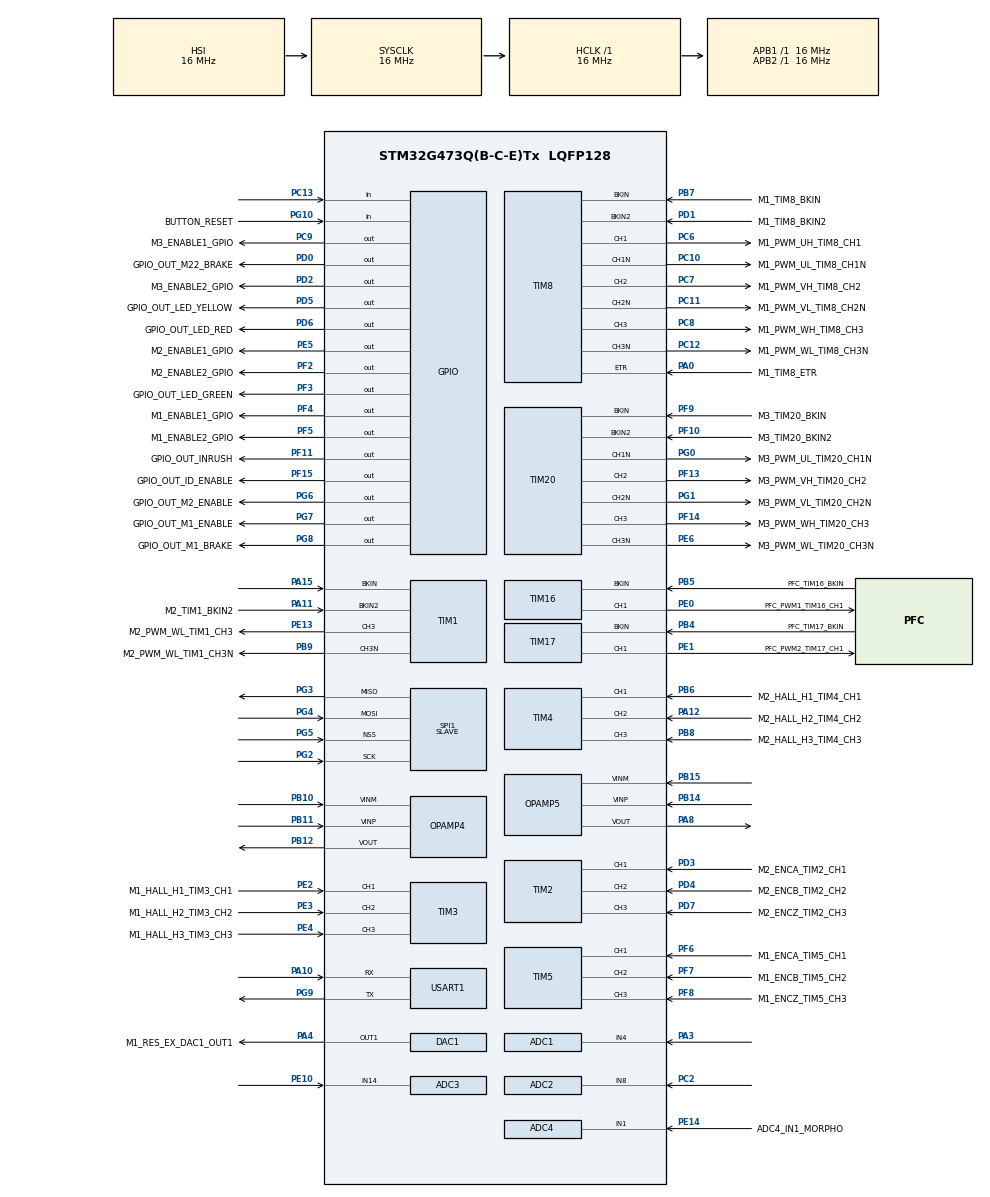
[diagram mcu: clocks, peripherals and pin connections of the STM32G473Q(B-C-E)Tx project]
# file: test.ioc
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ADC1.Channel-0\#ChannelRegularConversion=ADC_CHANNEL_4
ADC1.ClockPrescaler=ADC_CLOCK_SYNC_PCLK_DIV1
ADC1.ContinuousConvMode=ENABLE
ADC1.DMAAccessModeView=ENABLE
ADC1.DMAContinuousRequests=ENABLE
ADC1.Mode=ADC_DUALMODE_REGSIMULT
ADC1.NbrOfConversionFlag=1
ADC1.OffsetNumber-0\#ChannelRegularConversion=ADC_OFFSET_NONE
ADC1.Rank-0\#ChannelRegularConversion=1
ADC1.SamplingTime-0\#ChannelRegularConversion=ADC_SAMPLETIME_2CYCLES_5
ADC1.TwoSamplingDelay=ADC_TWOSAMPLINGDELAY_12CYCLES
ADC1.master=1
ADC2.Channel-1\#ChannelRegularConversion=ADC_CHANNEL_8
ADC2.ClockPrescaler=ADC_CLOCK_SYNC_PCLK_DIV1
ADC2.ContinuousConvMode=ENABLE
ADC2.DMAAccessModeView=ENABLE
ADC2.DMAContinuousRequests=DISABLE
ADC2.EnableAnalogWatchDog3=false
ADC2.Mode=ADC_DUALMODE_REGSIMULT
ADC2.NbrOfConversion=1
ADC2.NbrOfConversionFlag=1
ADC2.OffsetNumber-1\#ChannelRegularConversion=ADC_OFFSET_NONE
ADC2.Overrun=ADC_OVR_DATA_PRESERVED
ADC2.Rank-1\#ChannelRegularConversion=1
ADC2.Resolution=ADC_RESOLUTION_12B
ADC2.SamplingTime-1\#ChannelRegularConversion=ADC_SAMPLETIME_2CYCLES_5
ADC2.TwoSamplingDelay=ADC_TWOSAMPLINGDELAY_12CYCLES
ADC3.Channel-2\#ChannelRegularConversion=ADC_CHANNEL_14
ADC3.ClockPrescaler=ADC_CLOCK_SYNC_PCLK_DIV1
ADC3.ContinuousConvMode=ENABLE
ADC3.DMAAccessModeView=ENABLE
ADC3.DMAContinuousRequests=ENABLE
ADC3.Mode=ADC_DUALMODE_REGSIMULT
ADC3.NbrOfConversionFlag=1
ADC3.OffsetNumber-2\#ChannelRegularConversion=ADC_OFFSET_NONE
ADC3.Rank-2\#ChannelRegularConversion=1
ADC3.SamplingTime-2\#ChannelRegularConversion=ADC_SAMPLETIME_2CYCLES_5
ADC3.TwoSamplingDelay=ADC_TWOSAMPLINGDELAY_12CYCLES
ADC3.master=1
ADC4.Channel-1\#ChannelRegularConversion=ADC_CHANNEL_1
ADC4.ClockPrescaler=ADC_CLOCK_SYNC_PCLK_DIV1
ADC4.DMAAccessModeView=ENABLE
ADC4.Mode=ADC_DUALMODE_REGSIMULT
ADC4.NbrOfConversionFlag=1
ADC4.OffsetNumber-1\#ChannelRegularConversion=ADC_OFFSET_NONE
ADC4.Rank-1\#ChannelRegularConversion=1
ADC4.SamplingTime-1\#ChannelRegularConversion=ADC_SAMPLETIME_2CYCLES_5
ADC4.TwoSamplingDelay=ADC_TWOSAMPLINGDELAY_12CYCLES
DAC1.DAC_Channel-DAC_OUT2_ExtAndInt=DAC_CHANNEL_2
Dma.ADC1.0.Direction=DMA_PERIPH_TO_MEMORY
Dma.ADC1.0.EventEnable=DISABLE
Dma.ADC1.0.Instance=DMA1_Channel4
Dma.ADC1.0.MemDataAlignment=DMA_MDATAALIGN_WORD
Dma.ADC1.0.MemInc=DMA_MINC_ENABLE
Dma.ADC1.0.Mode=DMA_CIRCULAR
Dma.ADC1.0.PeriphDataAlignment=DMA_PDATAALIGN_WORD
Dma.ADC1.0.PeriphInc=DMA_PINC_DISABLE
Dma.ADC1.0.Polarity=HAL_DMAMUX_REQ_GEN_RISING
Dma.ADC1.0.Priority=DMA_PRIORITY_HIGH
Dma.ADC1.0.RequestNumber=1
Dma.ADC1.0.SignalID=NONE
Dma.ADC1.0.SyncEnable=DISABLE
Dma.ADC1.0.SyncPolarity=HAL_DMAMUX_SYNC_NO_EVENT
Dma.ADC1.0.SyncRequestNumber=1
Dma.ADC1.0.SyncSignalID=NONE
Dma.ADC3.1.Direction=DMA_PERIPH_TO_MEMORY
Dma.ADC3.1.EventEnable=DISABLE
Dma.ADC3.1.Instance=DMA2_Channel1
Dma.ADC3.1.MemDataAlignment=DMA_MDATAALIGN_WORD
Dma.ADC3.1.MemInc=DMA_MINC_ENABLE
Dma.ADC3.1.Mode=DMA_CIRCULAR
Dma.ADC3.1.PeriphDataAlignment=DMA_PDATAALIGN_WORD
Dma.ADC3.1.PeriphInc=DMA_PINC_DISABLE
Dma.ADC3.1.Polarity=HAL_DMAMUX_REQ_GEN_RISING
Dma.ADC3.1.Priority=DMA_PRIORITY_HIGH
Dma.ADC3.1.RequestNumber=1
Dma.ADC3.1.SignalID=NONE
Dma.ADC3.1.SyncEnable=DISABLE
Dma.ADC3.1.SyncPolarity=HAL_DMAMUX_SYNC_NO_EVENT
Dma.ADC3.1.SyncRequestNumber=1
Dma.ADC3.1.SyncSignalID=NONE
Dma.Request0=ADC1
Dma.Request1=ADC3
Mcu.Family=STM32G4
Mcu.Name=STM32G473Q(B-C-E)Tx
Mcu.Package=LQFP128
NVIC.ADC1_2_IRQn=true\:1\:0\:true\:false\:true\:true\:true\:true
NVIC.DMA1_Channel4_IRQn=true\:0\:0\:false\:false\:true\:false\:true\:true
NVIC.DMA2_Channel1_IRQn=true\:0\:0\:false\:false\:true\:false\:true\:true
NVIC.PriorityGroup=NVIC_PRIORITYGROUP_4
PA0.GPIO_Label=M1_TIM8_ETR
PA0.Signal=S_TIM8_ETR
PA10.Mode=Asynchronous
PA10.Signal=USART1_RX
PA11.GPIO_Label=M2_TIM1_BKIN2
PA11.Mode=Activate-Break-Input-2
PA11.Signal=TIM1_BKIN2
PA12.GPIO_Label=M2_HALL_H2_TIM4_CH2
PA12.Signal=S_TIM4_CH2
PA13.Mode=Trace_Asynchronous_SW
PA13.Signal=SYS_JTMS-SWDIO
PA14.Mode=Trace_Asynchronous_SW
PA14.Signal=SYS_JTCK-SWCLK
PA15.Mode=Activate-Break-Input
PA15.Signal=TIM1_BKIN
PA2.GPIO_Mode=GPIO_MODE_ANALOG
PA2.GPIO_PuPd=GPIO_NOPULL
PA2.Signal=ADC1_IN3
PA3.Mode=IN4-Single-Ended
PA3.Signal=ADC1_IN4
PA4.GPIO_Label=M1_RES_EX_DAC1_OUT1
PA4.Signal=COMP_DAC11_group
PA6.GPIO_Label=M3_TEMP_ID_ADC2IN3
PA6.Signal=ADC2_IN3
PA8.Mode=Standalone
PA8.Signal=OPAMP5_VOUT
PB0.Signal=OPAMP3_VINP
PB1.Signal=OPAMP3_VOUT
PB10.Mode=Standalone
PB10.Signal=OPAMP4_VINM
PB11.Mode=Standalone
PB11.Signal=OPAMP4_VINP
PB12.Mode=Standalone
PB12.Signal=OPAMP4_VOUT
PB13.GPIO_Label=M1_VBUS_ADC3_IN5
PB13.Signal=ADC3_IN5
PB14.Mode=Standalone
PB14.Signal=OPAMP5_VINP
PB15.Mode=Standalone
PB15.Signal=OPAMP5_VINM
PB3.Mode=Trace_Asynchronous_SW
PB3.Signal=SYS_JTDO-SWO
PB4.GPIO_Label=PFC_TIM17_BKIN
PB4.Mode=Activate-Break-Input
PB4.Signal=TIM17_BKIN
PB5.GPIO_Label=PFC_TIM16_BKIN
PB5.Mode=Activate-Break-Input
PB5.Signal=TIM16_BKIN
PB6.GPIO_Label=M2_HALL_H1_TIM4_CH1
PB6.Signal=S_TIM4_CH1
PB7.GPIO_Label=M1_TIM8_BKIN
PB7.Mode=Activate-Break-Input
PB7.Signal=TIM8_BKIN
PB8-BOOT0.GPIO_Label=M2_HALL_H3_TIM4_CH3
PB8-BOOT0.Signal=S_TIM4_CH3
PB9.GPIO_Label=M2_PWM_WL_TIM1_CH3N
PB9.Mode=PWM Generation3 CH3 CH3N
PB9.Signal=TIM1_CH3N
PC0.Signal=ADC2_IN6
PC10.GPIO_Label=M1_PWM_UL_TIM8_CH1N
PC10.Mode=PWM Generation1 CH1 CH1N
PC10.Signal=TIM8_CH1N
PC11.GPIO_Label=M1_PWM_VL_TIM8_CH2N
PC11.Mode=Output Compare2 CH2 CH2N
PC11.Signal=TIM8_CH2N
PC12.GPIO_Label=M1_PWM_WL_TIM8_CH3N
PC12.Mode=Output Compare3 CH3 CH3N
PC12.Signal=TIM8_CH3N
PC13.GPIO_PuPd=GPIO_PULLUP
PC13.Signal=GPIO_Input
PC14-OSC32_IN.Mode=LSE-External-Oscillator
PC14-OSC32_IN.Signal=RCC_OSC32_IN
PC15-OSC32_OUT.Mode=LSE-External-Oscillator
PC15-OSC32_OUT.Signal=RCC_OSC32_OUT
PC2.GPIO_Mode=GPIO_MODE_ANALOG
PC2.GPIO_PuPd=GPIO_NOPULL
PC2.Mode=IN8-Single-Ended
PC2.Signal=ADC2_IN8
PC3.Signal=ADC2_IN9
PC4.GPIO_Label=M2_TEMP_ID_ADC2_IN5
PC4.Signal=ADC2_IN5
PC5.GPIO_Label=PFC_AC_ZC_ADC2_IN11
PC5.Signal=ADC2_IN11
PC6.GPIO_Label=M1_PWM_UH_TIM8_CH1
PC6.Signal=S_TIM8_CH1
PC7.GPIO_Label=M1_PWM_VH_TIM8_CH2
PC7.Signal=S_TIM8_CH2
PC8.GPIO_Label=M1_PWM_WH_TIM8_CH3
PC8.Signal=S_TIM8_CH3
PC9.GPIO_Label=M3_ENABLE1_GPIO
PC9.Signal=GPIO_Output
PD0.GPIO_Label=GPIO_OUT_M22_BRAKE
PD0.Signal=GPIO_Output
PD1.GPIO_Label=M1_TIM8_BKIN2
PD1.Mode=Activate-Break-Input-2
PD1.Signal=TIM8_BKIN2
PD2.GPIO_Label=M3_ENABLE2_GPIO
PD2.Signal=GPIO_Output
PD3.GPIO_Label=M2_ENCA_TIM2_CH1
PD3.Signal=S_TIM2_CH1
PD4.GPIO_Label=M2_ENCB_TIM2_CH2
PD4.Signal=S_TIM2_CH2
PD5.GPIO_Label=GPIO_OUT_LED_YELLOW
PD5.Signal=GPIO_Output
PD6.GPIO_Label=GPIO_OUT_LED_RED
PD6.Signal=GPIO_Output
PD7.GPIO_Label=M2_ENCZ_TIM2_CH3
PD7.Signal=S_TIM2_CH3
PE0.GPIO_Label=PFC_PWM1_TIM16_CH1
PE0.Signal=S_TIM16_CH1
PE1.GPIO_Label=PFC_PWM2_TIM17_CH1
PE1.Signal=S_TIM17_CH1
PE10.Mode=IN14-Single-Ended
PE10.Signal=ADC3_IN14
PE11.GPIO_Label=M2_PWM_VH_TIM1_CH2
PE11.Signal=S_TIM1_CH2
PE13.GPIO_Label=M2_PWM_WL_TIM1_CH3
PE13.Signal=S_TIM1_CH3
PE14.GPIO_Label=ADC4_IN1_MORPHO
PE14.Mode=IN1-Single-Ended
PE14.Signal=ADC4_IN1
PE15.GPIO_Label=M1_TEMP_ID_ADC4_IN2
PE15.Signal=ADC4_IN2
PE2.GPIO_Label=M1_HALL_H1_TIM3_CH1
PE2.Signal=S_TIM3_CH1
PE3.GPIO_Label=M1_HALL_H2_TIM3_CH2
PE3.Signal=S_TIM3_CH2
PE4.GPIO_Label=M1_HALL_H3_TIM3_CH3
PE4.Signal=S_TIM3_CH3
PE5.GPIO_Label=M2_ENABLE1_GPIO
PE5.Signal=GPIO_Output
PE6.GPIO_Label=M3_PWM_WL_TIM20_CH3N
PE6.Mode=Output Compare3 CH3 CH3N
PE6.Signal=TIM20_CH3N
PE9.GPIO_Label=M2_PWM_UH_TIM1_CH1
PE9.Signal=S_TIM1_CH1
PF0-OSC_IN.Mode=HSE-External-Clock-Source
PF0-OSC_IN.Signal=RCC_OSC_IN
PF1-OSC_OUT.GPIO_Label=ADC2_IN10_PFC_AC_V
PF1-OSC_OUT.Signal=ADC2_IN10
PF10.GPIO_Label=M3_TIM20_BKIN2
PF10.Mode=Activate-Break-Input-2
PF10.Signal=TIM20_BKIN2
PF11.GPIO_Label=GPIO_OUT_INRUSH
PF11.Signal=GPIO_Output
PF12.GPIO_Label=M3_PWM_UH_TIM20_CH1
PF12.Signal=S_TIM20_CH1
PF13.GPIO_Label=M3_PWM_VH_TIM20_CH2
PF13.Signal=S_TIM20_CH2
PF14.GPIO_Label=M3_PWM_WH_TIM20_CH3
PF14.Signal=S_TIM20_CH3
PF15.GPIO_Label=GPIO_OUT_ID_ENABLE
PF15.Signal=GPIO_Output
PF2.GPIO_Label=M2_ENABLE2_GPIO
PF2.GPIO_PuPd=GPIO_NOPULL
PF2.GPIO_Speed=GPIO_SPEED_FREQ_VERY_HIGH
PF2.Signal=GPIO_Output
PF3.GPIO_Label=GPIO_OUT_LED_GREEN
PF3.Signal=GPIO_Output
PF4.GPIO_Label=M1_ENABLE1_GPIO
PF4.Signal=GPIO_Output
PF5.GPIO_Label=M1_ENABLE2_GPIO
PF5.Signal=GPIO_Output
PF6.GPIO_Label=M1_ENCA_TIM5_CH1
PF6.Signal=S_TIM5_CH1
PF7.GPIO_Label=M1_ENCB_TIM5_CH2
PF7.Signal=S_TIM5_CH2
PF8.GPIO_Label=M1_ENCZ_TIM5_CH3
PF8.Signal=S_TIM5_CH3
PF9.GPIO_Label=M3_TIM20_BKIN
PF9.Mode=Activate-Break-Input
PF9.Signal=TIM20_BKIN
PG0.GPIO_Label=M3_PWM_UL_TIM20_CH1N
PG0.Mode=PWM Generation1 CH1 CH1N
PG0.Signal=TIM20_CH1N
PG1.GPIO_Label=M3_PWM_VL_TIM20_CH2N
PG1.Mode=PWM Generation2 CH2 CH2N
PG1.Signal=TIM20_CH2N
PG10-NRST.GPIO_Label=BUTTON_RESET
PG10-NRST.Signal=GPIO_Input
PG2.Mode=Full_Duplex_Slave
PG2.Signal=SPI1_SCK
PG3.Mode=Full_Duplex_Slave
PG3.Signal=SPI1_MISO
PG4.Mode=Full_Duplex_Slave
PG4.Signal=SPI1_MOSI
PG5.Mode=NSS_Signal_Hard_Input
PG5.Signal=SPI1_NSS
PG6.GPIO_Label=GPIO_OUT_M2_ENABLE
PG6.Signal=GPIO_Output
PG7.GPIO_Label=GPIO_OUT_M1_ENABLE
PG7.Signal=GPIO_Output
PG8.GPIO_Label=GPIO_OUT_M1_BRAKE
PG8.Signal=GPIO_Output
PG9.Mode=Asynchronous
PG9.Signal=USART1_TX
ProjectManager.HeapSize=0x200
ProjectManager.StackSize=0x400
ProjectManager.TargetToolchain=STM32CubeIDE
RCC.ADC12Freq_Value=16000000
RCC.ADC345Freq_Value=16000000
RCC.AHBFreq_Value=16000000
RCC.APB1Freq_Value=16000000
RCC.APB1TimFreq_Value=16000000
RCC.APB2Freq_Value=16000000
RCC.APB2TimFreq_Value=16000000
RCC.CortexFreq_Value=16000000
RCC.EXTERNAL_CLOCK_VALUE=12288000
RCC.HCLKFreq_Value=16000000
RCC.HSE_VALUE=8000000
RCC.HSI48_VALUE=48000000
RCC.HSI_VALUE=16000000
RCC.SYSCLKFreq_VALUE=16000000
RCC.USBFreq_Value=64000000
RCC.VCOOutputFreq_Value=128000000
SH.COMP_DAC11_group.0=DAC1_OUT1,DAC_OUT1_ExtAndInt
SH.S_TIM16_CH1.0=TIM16_CH1,Output Compare1 CH1
SH.S_TIM17_CH1.0=TIM17_CH1,Output Compare1 CH1
SH.S_TIM1_CH1.0=TIM1_CH1
SH.S_TIM1_CH2.0=TIM1_CH2
SH.S_TIM1_CH3.0=TIM1_CH3,PWM Generation3 CH3 CH3N
SH.S_TIM20_CH1.0=TIM20_CH1
SH.S_TIM20_CH2.0=TIM20_CH2,PWM Generation2 CH2 CH2N
SH.S_TIM20_CH3.0=TIM20_CH3,Output Compare3 CH3 CH3N
SH.S_TIM2_CH1.0=TIM2_CH1,Encoder_Interface
SH.S_TIM2_CH2.0=TIM2_CH2,Encoder_Interface
SH.S_TIM2_CH3.0=TIM2_CH3,Input_Capture3_from_TI3
SH.S_TIM3_CH1.0=TIM3_CH1,Xored_Inputs_Hall_Sensor_Interface
SH.S_TIM3_CH2.0=TIM3_CH2,Xored_Inputs_Hall_Sensor_Interface
SH.S_TIM3_CH3.0=TIM3_CH3,Xored_Inputs_Hall_Sensor_Interface
SH.S_TIM4_CH1.0=TIM4_CH1,Xored_Inputs_Hall_Sensor_Interface
SH.S_TIM4_CH2.0=TIM4_CH2,Xored_Inputs_Hall_Sensor_Interface
SH.S_TIM4_CH3.0=TIM4_CH3,Xored_Inputs_Hall_Sensor_Interface
SH.S_TIM5_CH1.0=TIM5_CH1,Encoder_Interface
SH.S_TIM5_CH2.0=TIM5_CH2,Encoder_Interface
SH.S_TIM5_CH3.0=TIM5_CH3,Input_Capture3_from_TI3
SH.S_TIM8_CH1.0=TIM8_CH1,PWM Generation1 CH1 CH1N
SH.S_TIM8_CH2.0=TIM8_CH2,Output Compare2 CH2 CH2N
SH.S_TIM8_CH3.0=TIM8_CH3,Output Compare3 CH3 CH3N
SH.S_TIM8_ETR.0=TIM8_ETR,ETR-as-clearing-source
SPI1.Direction=SPI_DIRECTION_2LINES
SPI1.Mode=SPI_MODE_SLAVE
SPI1.VirtualNSS=VM_NSSHARD
SPI1.VirtualType=VM_SLAVE
TIM1.Channel-PWM\ Generation3\ CH3\ CH3N=TIM_CHANNEL_3
TIM16.Channel=TIM_CHANNEL_1
TIM17.Channel=TIM_CHANNEL_1
TIM2.Channel-Input_Capture3_from_TI3=TIM_CHANNEL_3
TIM20.Channel-Output\ Compare3\ CH3\ CH3N=TIM_CHANNEL_3
TIM20.Channel-PWM\ Generation1\ CH1\ CH1N=TIM_CHANNEL_1
TIM20.Channel-PWM\ Generation2\ CH2\ CH2N=TIM_CHANNEL_2
TIM5.Channel-Input_Capture3_from_TI3=TIM_CHANNEL_3
TIM8.Channel-Output\ Compare2\ CH2\ CH2N=TIM_CHANNEL_2
TIM8.Channel-Output\ Compare3\ CH3\ CH3N=TIM_CHANNEL_3
TIM8.Channel-PWM\ Generation1\ CH1\ CH1N=TIM_CHANNEL_1
USART1.VirtualMode-Asynchronous=VM_ASYNC
VP_SYS_VS_DBSignals.Mode=DisableDeadBatterySignals
VP_TIM16_VS_ClockSourceINT.Mode=Enable_Timer
VP_TIM17_VS_ClockSourceINT.Mode=Enable_Timer
VP_TIM1_VS_ClockSourceITR.Mode=TriggerSource_ITR1
VP_TIM1_VS_ControllerModeTrigger.Mode=Trigger Mode
VP_TIM20_VS_ClockSourceITR.Mode=TriggerSource_ITR1
VP_TIM20_VS_ControllerModeTrigger.Mode=Trigger Mode
VP_TIM3_VS_ClockSourceINT.Mode=Internal
VP_TIM4_VS_ClockSourceINT.Mode=Internal
VP_TIM8_VS_ClockSourceITR.Mode=TriggerSource_ITR1
VP_TIM8_VS_ControllerModeTrigger.Mode=Trigger Mode
board=B-G473E-ZEST1S

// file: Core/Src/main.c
/* USER CODE BEGIN Header */
/**
  ******************************************************************************
  * @file           : main.c
  * @brief          : Main program body
  ******************************************************************************
  * @attention
  *
  * Copyright (c) 2025 STMicroelectronics.
  * All rights reserved.
  *
  * This software is licensed under terms that can be found in the LICENSE file
  * in the root directory of this software component.
  * If no LICENSE file comes with this software, it is provided AS-IS.
  *
  ******************************************************************************
  */
/* USER CODE END Header */
#include "main.h"

/* USER CODE BEGIN Includes */
#include <stdio.h>
#include <string.h>

/* USER CODE END Includes */

/* USER CODE BEGIN PD */
#define ADC_BUF_LEN 2048

#include "arm_math.h"

#define ADC_MAX 2048
/* USER CODE END PD */

ADC_HandleTypeDef hadc1;
ADC_HandleTypeDef hadc2;
ADC_HandleTypeDef hadc3;
ADC_HandleTypeDef hadc4;
DMA_HandleTypeDef hdma_adc1;
DMA_HandleTypeDef hdma_adc3;

DAC_HandleTypeDef hdac1;

OPAMP_HandleTypeDef hopamp4;
OPAMP_HandleTypeDef hopamp5;

SPI_HandleTypeDef hspi1;

TIM_HandleTypeDef htim1;
TIM_HandleTypeDef htim2;
TIM_HandleTypeDef htim3;
TIM_HandleTypeDef htim4;
TIM_HandleTypeDef htim5;
TIM_HandleTypeDef htim8;
TIM_HandleTypeDef htim16;
TIM_HandleTypeDef htim17;
TIM_HandleTypeDef htim20;

UART_HandleTypeDef huart1;

/* USER CODE BEGIN PV */
uint16_t adc_buf1[2 * ADC_BUF_LEN]; //The reason this is a 16 bit buffer is that we are writing a 32 bit number which contains two different 16 bit values. Instead of writing it to an
//array of 32 bit numbers with a length of ADC_BUF_LEN, why not write it to an array of 16 bit numbers with a length of ADC_BUF_LEN * 2 to make it easier on our brain?
uint16_t adc_buf3[2 * ADC_BUF_LEN];

uint32_t values;
uint32_t values2;
char msg[30] = "Starting code\r\n";
char errMsg[15] = "Error in DWT\r\n";
char msg3[30] = "Beginning transmission...\r\n";
uint32_t samplingFreq;

/*
uint16_t firstHex;
uint16_t secondHex;
uint16_t thirdHex;
uint16_t fourthHex;

uint8_t delay;

uint32_t au32_initial_ticksADC1 = 0;
uint32_t au32_midway_ticksADC1 = 0;
uint32_t au32_end_ticksADC1 = 0;~

uint32_t au32_initial_ticksADC3 = 0;
uint32_t au32_midway_ticksADC3 = 0;
uint32_t au32_end_ticksADC3 = 0;

uint16_t numOfConversions = 0;
uint16_t indexStoppedADC1 = 0;
uint16_t indexStoppedADC3 = 0;
*/

uint32_t au32_initial_ticksADC1 = 0;
uint32_t au32_midway_ticksADC1 = 0;
uint32_t au32_end_ticksADC1 = 0;

uint32_t au32_initial_ticksADC3 = 0;
uint32_t au32_midway_ticksADC3 = 0;
uint32_t au32_end_ticksADC3 = 0;

arm_rfft_fast_instance_f32 fftHandler;

float32_t fftBufInADC1[ADC_BUF_LEN];
float32_t fftBufOutADC1[ADC_BUF_LEN];

float32_t fftBufInADC2[ADC_BUF_LEN];
float32_t fftBufOutADC2[ADC_BUF_LEN];

float32_t fftBufInADC3[ADC_BUF_LEN];
float32_t fftBufOutADC3[ADC_BUF_LEN];

float32_t fftBufInADC4[ADC_BUF_LEN];
float32_t fftBufOutADC4[ADC_BUF_LEN];

uint8_t fftFlagADC12 = 0;
uint8_t fftFlagADC34 = 0;

/* USER CODE END PV */

void SystemClock_Config(void);
static void MX_GPIO_Init(void);
static void MX_DMA_Init(void);
static void MX_ADC2_Init(void);
static void MX_DAC1_Init(void);
static void MX_OPAMP4_Init(void);
static void MX_OPAMP5_Init(void);
static void MX_SPI1_Init(void);
static void MX_TIM1_Init(void);
static void MX_TIM2_Init(void);
static void MX_TIM3_Init(void);
static void MX_TIM4_Init(void);
static void MX_TIM5_Init(void);
static void MX_TIM8_Init(void);
static void MX_TIM16_Init(void);
static void MX_TIM17_Init(void);
static void MX_TIM20_Init(void);
static void MX_USART1_UART_Init(void);
static void MX_ADC1_Init(void);
static void MX_ADC3_Init(void);
static void MX_ADC4_Init(void);
/* USER CODE BEGIN PFP */
uint32_t DWT_Delay_Init(void);
void Process_HalfBuffer(ADC_HandleTypeDef* hadc, int cycle);
/* USER CODE END PFP */

int main(void)
{

  /* MCU Configuration--------------------------------------------------------*/

  /* Reset of all peripherals, Initializes the Flash interface and the Systick. */
  HAL_Init();

  /* USER CODE BEGIN Init */
  char bufferNumbers[60];
  const char FFT1[30] = "ADC12 Triggered\r\n";
  const char FFT3[30] = "ADC34 Triggered\r\n";
  const char endFFT[30] = "Finished Transmission\r\n";
  uint32_t frequency;
  char endMessage[200];

  /* USER CODE END Init */

  /* Configure the system clock */
  SystemClock_Config();

  /* Initialize all configured peripherals */
  MX_GPIO_Init();
  MX_DMA_Init();
  MX_ADC2_Init();
  MX_DAC1_Init();
  MX_OPAMP4_Init();
  MX_OPAMP5_Init();
  MX_SPI1_Init();
  MX_TIM1_Init();
  MX_TIM2_Init();
  MX_TIM3_Init();
  MX_TIM4_Init();
  MX_TIM5_Init();
  MX_TIM8_Init();
  MX_TIM16_Init();
  MX_TIM17_Init();
  MX_TIM20_Init();
  MX_USART1_UART_Init();
  MX_ADC1_Init();
  MX_ADC3_Init();
  MX_ADC4_Init();
  /* USER CODE BEGIN 2 */

  if(DWT_Delay_Init())
  {
	  Error_Handler();
  }

  /*
  HAL_UART_Transmit(&huart1, (uint8_t*) msg, strlen(msg), HAL_MAX_DELAY);
  */

  HAL_GPIO_WritePin(GPIOF, GPIO_PIN_2, GPIO_PIN_RESET);

  arm_rfft_fast_init_f32(&fftHandler, ADC_BUF_LEN);

  au32_initial_ticksADC1 = DWT->CYCCNT;

  HAL_ADCEx_MultiModeStart_DMA(&hadc1, (uint32_t *) adc_buf1, ADC_BUF_LEN); //I figured out how the dual synchronous simultaneous mode works, but it broke randomly. For some reason, it is only writing the value of one channel to
  //the buffer. I have no idea why.

  //HAL_ADCEx_MultiModeStart_DMA(&hadc3, (uint32_t *) adc_buf3, ADC_BUF_LEN);

  //HAL_ADCEx_MultiModeStart_DMA(&hadc3, adc_buf3, ADC_BUF_LEN);

  /* USER CODE END 2 */

  /* Infinite loop */
  /* USER CODE BEGIN WHILE */
  while (1)
  {
	  //I disabled DMA continuous conversion mode and now nothing works. When I had it enabled DMA was over-running. I don't know why or even what this function really does.
	  //I think I might be trying to do too much without knowing enough. Maybe I should read more before trying to troubleshoot. I am mainly relying on STM32 forum boards, but
	  //a lot of them make references to manuals I am clueless about or how to find. I think I might need to slow down and actually take time to understand what I am doing.

	  HAL_Delay(1000);

	  /*
	if(indexStoppedADC1)
	{
		HAL_UART_Transmit(&huart1, (uint8_t*) msg3, strlen(msg3), HAL_MAX_DELAY);

		for(int j = 0; j < ADC_BUF_LEN; j += 2)
		{
			sprintf(bufferNumbers, "%u,%u\r\n", adc_buf1[j], adc_buf1[j + 1]);
			HAL_UART_Transmit(&huart1, (uint8_t*) bufferNumbers, strlen(bufferNumbers), HAL_MAX_DELAY);
		}

		sprintf(endMessage, "After starting at %lu. It took %lu clock cycles to read %d times. The midway point occurred at  %lu clock cycles\r\n", au32_initial_ticksADC1, au32_end_ticksADC1 - au32_initial_ticksADC1, ADC_BUF_LEN/2, au32_midway_ticksADC1);
		HAL_UART_Transmit(&huart1, (uint8_t*) endMessage, strlen(endMessage), HAL_MAX_DELAY);

		float samplingTime;
		samplingTime = (float) (au32_end_ticksADC1 - au32_initial_ticksADC1)/HAL_RCC_GetHCLKFreq() * 1000000;

		double samplingRate;
		samplingRate = (ADC_BUF_LEN/2) / samplingTime;

		sprintf(endMessage, "It took %1.3f microseconds to read %d times, corresponding to a sampling  rate of %1.2lf MSPS. Index: %u. ADC1\r\n", samplingTime, ADC_BUF_LEN/2, samplingRate, indexStoppedADC1);

		HAL_UART_Transmit(&huart1, (uint8_t*) endMessage, strlen(endMessage), HAL_MAX_DELAY);
	}

	if(indexStoppedADC3)
	{
		HAL_UART_Transmit(&huart1, (uint8_t*) msg3, strlen(msg3), HAL_MAX_DELAY);

		for(int j = 0; j < ADC_BUF_LEN; j += 2)
		{
			sprintf(bufferNumbers, "%u,%u\r\n", adc_buf1[j], adc_buf1[j + 1]);
			HAL_UART_Transmit(&huart1, (uint8_t*) bufferNumbers, strlen(bufferNumbers), HAL_MAX_DELAY);
		}

		sprintf(endMessage, "After starting at %lu. It took %lu clock cycles to read %d times. The midway point occurred at  %lu clock cycles\r\n", au32_initial_ticksADC1, au32_end_ticksADC1 - au32_initial_ticksADC1, ADC_BUF_LEN/2, au32_midway_ticksADC1);
		HAL_UART_Transmit(&huart1, (uint8_t*) endMessage, strlen(endMessage), HAL_MAX_DELAY);

		float samplingTime;
		samplingTime = (float) (au32_end_ticksADC1 - au32_initial_ticksADC1)/HAL_RCC_GetHCLKFreq() * 1000000;

		double samplingRate;
		samplingRate = (ADC_BUF_LEN/2) / samplingTime;

		sprintf(endMessage, "It took %1.3f microseconds to read %d times, corresponding to a sampling  rate of %1.2lf MSPS. Index: %u. ADC3\r\n", samplingTime, ADC_BUF_LEN/2, samplingRate, indexStoppedADC3);

		HAL_UART_Transmit(&huart1, (uint8_t*) endMessage, strlen(endMessage), HAL_MAX_DELAY);
	}
		  */

	//Now that I have the DSP Library installed and the ADCs working properly. All that is left to do is to call an FFT on the data I collected and see if it actually works :)
	if(fftFlagADC12)
	{

		HAL_GPIO_WritePin(GPIOF, GPIO_PIN_2, GPIO_PIN_RESET);
		HAL_UART_Transmit(&huart1, (uint8_t*) FFT1, strlen(FFT1), HAL_MAX_DELAY);

		for(int j = 0; j < ADC_BUF_LEN; j += 2)
		{
			frequency = j * samplingFreq / (ADC_BUF_LEN);
 			sprintf(bufferNumbers, "%lf,%lf,%u, %d\r\n", fftBufOutADC1[j],fftBufOutADC1[j + 1], frequency, j);
			HAL_UART_Transmit(&huart1, (uint8_t*) bufferNumbers, strlen(bufferNumbers), HAL_MAX_DELAY);
		}

		HAL_UART_Transmit(&huart1, (uint8_t*) endFFT, strlen(endFFT), HAL_MAX_DELAY);

		sprintf(endMessage, "After starting at %lu. It took %lu clock cycles to read %d times. The midway point occurred at  %lu clock cycles\r\n", au32_initial_ticksADC1, au32_end_ticksADC1 - au32_initial_ticksADC1, ADC_BUF_LEN/2, au32_midway_ticksADC1);
		HAL_UART_Transmit(&huart1, (uint8_t*) endMessage, strlen(endMessage), HAL_MAX_DELAY);

		float samplingTime;
		samplingTime = (float) (au32_end_ticksADC1 - au32_initial_ticksADC1)/HAL_RCC_GetHCLKFreq() * 1000000;

		double samplingRate;
		samplingRate = (ADC_BUF_LEN) / samplingTime;

		sprintf(endMessage, "It took %1.3f microseconds to read %d times, corresponding to a sampling  rate of %1.6lf MSPS ADC1\r\n", samplingTime, ADC_BUF_LEN, samplingRate);
		HAL_UART_Transmit(&huart1, (uint8_t*) endMessage, strlen(endMessage), HAL_MAX_DELAY);

		HAL_Delay(1000);
		break; //MAKE SURE TO REMOVE THIS. I am just including it because I want to keep UART clear after 1st execution
	}

	if(fftFlagADC34)
	{
		HAL_UART_Transmit(&huart1, (uint8_t*) FFT3, strlen(FFT3), HAL_MAX_DELAY);
	}

    /* USER CODE END WHILE */

  }
}

void SystemClock_Config(void)
{
  RCC_OscInitTypeDef RCC_OscInitStruct = {0};
  RCC_ClkInitTypeDef RCC_ClkInitStruct = {0};

  /** Configure the main internal regulator output voltage
  */
  HAL_PWREx_ControlVoltageScaling(PWR_REGULATOR_VOLTAGE_SCALE1);

  /** Initializes the RCC Oscillators according to the specified parameters
  * in the RCC_OscInitTypeDef structure.
  */
  RCC_OscInitStruct.OscillatorType = RCC_OSCILLATORTYPE_HSI;
  RCC_OscInitStruct.HSIState = RCC_HSI_ON;
  RCC_OscInitStruct.HSICalibrationValue = RCC_HSICALIBRATION_DEFAULT;
  RCC_OscInitStruct.PLL.PLLState = RCC_PLL_NONE;
  if (HAL_RCC_OscConfig(&RCC_OscInitStruct) != HAL_OK)
  {
    Error_Handler();
  }

  /** Initializes the CPU, AHB and APB buses clocks
  */
  RCC_ClkInitStruct.ClockType = RCC_CLOCKTYPE_HCLK|RCC_CLOCKTYPE_SYSCLK
                              |RCC_CLOCKTYPE_PCLK1|RCC_CLOCKTYPE_PCLK2;
  RCC_ClkInitStruct.SYSCLKSource = RCC_SYSCLKSOURCE_HSI;
  RCC_ClkInitStruct.AHBCLKDivider = RCC_SYSCLK_DIV1;
  RCC_ClkInitStruct.APB1CLKDivider = RCC_HCLK_DIV1;
  RCC_ClkInitStruct.APB2CLKDivider = RCC_HCLK_DIV1;

  if (HAL_RCC_ClockConfig(&RCC_ClkInitStruct, FLASH_LATENCY_0) != HAL_OK)
  {
    Error_Handler();
  }
}

static void MX_ADC1_Init(void)
{

  ADC_MultiModeTypeDef multimode = {0};
  ADC_ChannelConfTypeDef sConfig = {0};

  /** Common config
  */
  hadc1.Instance = ADC1;
  hadc1.Init.ClockPrescaler = ADC_CLOCK_SYNC_PCLK_DIV1;
  hadc1.Init.Resolution = ADC_RESOLUTION_12B;
  hadc1.Init.DataAlign = ADC_DATAALIGN_RIGHT;
  hadc1.Init.GainCompensation = 0;
  hadc1.Init.ScanConvMode = ADC_SCAN_DISABLE;
  hadc1.Init.EOCSelection = ADC_EOC_SINGLE_CONV;
  hadc1.Init.LowPowerAutoWait = DISABLE;
  hadc1.Init.ContinuousConvMode = ENABLE;
  hadc1.Init.NbrOfConversion = 1;
  hadc1.Init.DiscontinuousConvMode = DISABLE;
  hadc1.Init.ExternalTrigConv = ADC_SOFTWARE_START;
  hadc1.Init.ExternalTrigConvEdge = ADC_EXTERNALTRIGCONVEDGE_NONE;
  hadc1.Init.DMAContinuousRequests = ENABLE;
  hadc1.Init.Overrun = ADC_OVR_DATA_PRESERVED;
  hadc1.Init.OversamplingMode = DISABLE;
  if (HAL_ADC_Init(&hadc1) != HAL_OK)
  {
    Error_Handler();
  }

  /** Configure the ADC multi-mode
  */
  multimode.Mode = ADC_DUALMODE_REGSIMULT;
  multimode.DMAAccessMode = ADC_DMAACCESSMODE_12_10_BITS;
  multimode.TwoSamplingDelay = ADC_TWOSAMPLINGDELAY_12CYCLES;
  if (HAL_ADCEx_MultiModeConfigChannel(&hadc1, &multimode) != HAL_OK)
  {
    Error_Handler();
  }

  /** Configure Regular Channel
  */
  sConfig.Channel = ADC_CHANNEL_4;
  sConfig.Rank = ADC_REGULAR_RANK_1;
  sConfig.SamplingTime = ADC_SAMPLETIME_2CYCLES_5;
  sConfig.SingleDiff = ADC_SINGLE_ENDED;
  sConfig.OffsetNumber = ADC_OFFSET_NONE;
  sConfig.Offset = 0;
  if (HAL_ADC_ConfigChannel(&hadc1, &sConfig) != HAL_OK)
  {
    Error_Handler();
  }
  /* USER CODE BEGIN ADC1_Init 2 */

  //It looks like (both experimentally and from the data sheet) that the two sampling delay is completely useless and has
  //nothing to do with what we are doing. It is only used in dual interleave mode.
  uint8_t resolution = 0;
  float samplingTime = 0;
  uint32_t fADC = 0;

  if (hadc1.Init.Resolution == ADC_RESOLUTION_6B)
  {
	  resolution = 6;
  } else if (hadc1.Init.Resolution == ADC_RESOLUTION_8B)
  {
	  resolution = 8;
  } else if (hadc1.Init.Resolution == ADC_RESOLUTION_10B)
  {
	  resolution = 10;
  } else if (hadc1.Init.Resolution == ADC_RESOLUTION_12B)
  {
	  resolution = 12;
  }

  switch (sConfig.SamplingTime) {
    case ADC_SAMPLETIME_2CYCLES_5:  samplingTime =  2.5f; break;
    case ADC_SAMPLETIME_6CYCLES_5:  samplingTime =  6.5f; break;
    case ADC_SAMPLETIME_12CYCLES_5: samplingTime = 12.5f; break;
    case ADC_SAMPLETIME_24CYCLES_5: samplingTime = 24.5f; break;
    case ADC_SAMPLETIME_47CYCLES_5: samplingTime = 47.5f; break;
    case ADC_SAMPLETIME_92CYCLES_5: samplingTime = 92.5f; break;
    case ADC_SAMPLETIME_247CYCLES_5: samplingTime = 247.5f; break;
    case ADC_SAMPLETIME_640CYCLES_5: samplingTime = 640.5f; break;
    default:                        samplingTime =  2.5f; break;
  }

  if (hadc1.Init.ClockPrescaler == ADC_CLOCK_SYNC_PCLK_DIV1)
  {
	  fADC =  HAL_RCC_GetSysClockFreq();
  } else if (hadc1.Init.ClockPrescaler == ADC_CLOCK_SYNC_PCLK_DIV2)
  {
	  fADC = HAL_RCC_GetSysClockFreq()/2;
  } else if (hadc1.Init.ClockPrescaler == ADC_CLOCK_SYNC_PCLK_DIV4)
  {
	  fADC = HAL_RCC_GetSysClockFreq()/4;
  }

  if (hadc1.Init.ClockPrescaler == ADC_CLOCK_SYNC_PCLK_DIV1)
  {
	  fADC =  HAL_RCC_GetPCLK2Freq();
  } else if (hadc1.Init.ClockPrescaler == ADC_CLOCK_SYNC_PCLK_DIV2)
  {
	  fADC = HAL_RCC_GetPCLK2Freq()/2;
  } else if (hadc1.Init.ClockPrescaler == ADC_CLOCK_SYNC_PCLK_DIV4)
  {
	  fADC = HAL_RCC_GetPCLK2Freq()/4;
  }

  samplingFreq = 0.5 * fADC / (samplingTime + resolution + 0.5); //For some mystery reason I need to divide by two to get the true sampling frequency
  //(probably has something to do with dual simultaneous mode)

  /* USER CODE END ADC1_Init 2 */

}

static void MX_ADC2_Init(void)
{

  ADC_ChannelConfTypeDef sConfig = {0};

  /** Common config
  */
  hadc2.Instance = ADC2;
  hadc2.Init.ClockPrescaler = ADC_CLOCK_SYNC_PCLK_DIV1;
  hadc2.Init.Resolution = ADC_RESOLUTION_12B;
  hadc2.Init.DataAlign = ADC_DATAALIGN_RIGHT;
  hadc2.Init.GainCompensation = 0;
  hadc2.Init.ScanConvMode = ADC_SCAN_DISABLE;
  hadc2.Init.EOCSelection = ADC_EOC_SINGLE_CONV;
  hadc2.Init.LowPowerAutoWait = DISABLE;
  hadc2.Init.ContinuousConvMode = ENABLE;
  hadc2.Init.NbrOfConversion = 1;
  hadc2.Init.DiscontinuousConvMode = DISABLE;
  hadc2.Init.DMAContinuousRequests = DISABLE;
  hadc2.Init.Overrun = ADC_OVR_DATA_PRESERVED;
  hadc2.Init.OversamplingMode = DISABLE;
  if (HAL_ADC_Init(&hadc2) != HAL_OK)
  {
    Error_Handler();
  }

  /** Configure Regular Channel
  */
  sConfig.Channel = ADC_CHANNEL_8;
  sConfig.Rank = ADC_REGULAR_RANK_1;
  sConfig.SamplingTime = ADC_SAMPLETIME_2CYCLES_5;
  sConfig.SingleDiff = ADC_SINGLE_ENDED;
  sConfig.OffsetNumber = ADC_OFFSET_NONE;
  sConfig.Offset = 0;
  if (HAL_ADC_ConfigChannel(&hadc2, &sConfig) != HAL_OK)
  {
    Error_Handler();
  }

}

static void MX_ADC3_Init(void)
{

  ADC_MultiModeTypeDef multimode = {0};
  ADC_ChannelConfTypeDef sConfig = {0};

  /** Common config
  */
  hadc3.Instance = ADC3;
  hadc3.Init.ClockPrescaler = ADC_CLOCK_SYNC_PCLK_DIV1;
  hadc3.Init.Resolution = ADC_RESOLUTION_12B;
  hadc3.Init.DataAlign = ADC_DATAALIGN_RIGHT;
  hadc3.Init.GainCompensation = 0;
  hadc3.Init.ScanConvMode = ADC_SCAN_DISABLE;
  hadc3.Init.EOCSelection = ADC_EOC_SINGLE_CONV;
  hadc3.Init.LowPowerAutoWait = DISABLE;
  hadc3.Init.ContinuousConvMode = ENABLE;
  hadc3.Init.NbrOfConversion = 1;
  hadc3.Init.DiscontinuousConvMode = DISABLE;
  hadc3.Init.ExternalTrigConv = ADC_SOFTWARE_START;
  hadc3.Init.ExternalTrigConvEdge = ADC_EXTERNALTRIGCONVEDGE_NONE;
  hadc3.Init.DMAContinuousRequests = ENABLE;
  hadc3.Init.Overrun = ADC_OVR_DATA_PRESERVED;
  hadc3.Init.OversamplingMode = DISABLE;
  if (HAL_ADC_Init(&hadc3) != HAL_OK)
  {
    Error_Handler();
  }

  /** Configure the ADC multi-mode
  */
  multimode.Mode = ADC_DUALMODE_REGSIMULT;
  multimode.DMAAccessMode = ADC_DMAACCESSMODE_12_10_BITS;
  multimode.TwoSamplingDelay = ADC_TWOSAMPLINGDELAY_12CYCLES;
  if (HAL_ADCEx_MultiModeConfigChannel(&hadc3, &multimode) != HAL_OK)
  {
    Error_Handler();
  }

  /** Configure Regular Channel
  */
  sConfig.Channel = ADC_CHANNEL_14;
  sConfig.Rank = ADC_REGULAR_RANK_1;
  sConfig.SamplingTime = ADC_SAMPLETIME_2CYCLES_5;
  sConfig.SingleDiff = ADC_SINGLE_ENDED;
  sConfig.OffsetNumber = ADC_OFFSET_NONE;
  sConfig.Offset = 0;
  if (HAL_ADC_ConfigChannel(&hadc3, &sConfig) != HAL_OK)
  {
    Error_Handler();
  }

}

static void MX_ADC4_Init(void)
{

  ADC_ChannelConfTypeDef sConfig = {0};

  /** Common config
  */
  hadc4.Instance = ADC4;
  hadc4.Init.ClockPrescaler = ADC_CLOCK_SYNC_PCLK_DIV1;
  hadc4.Init.Resolution = ADC_RESOLUTION_12B;
  hadc4.Init.DataAlign = ADC_DATAALIGN_RIGHT;
  hadc4.Init.GainCompensation = 0;
  hadc4.Init.ScanConvMode = ADC_SCAN_DISABLE;
  hadc4.Init.EOCSelection = ADC_EOC_SINGLE_CONV;
  hadc4.Init.LowPowerAutoWait = DISABLE;
  hadc4.Init.ContinuousConvMode = ENABLE;
  hadc4.Init.NbrOfConversion = 1;
  hadc4.Init.DiscontinuousConvMode = DISABLE;
  hadc4.Init.DMAContinuousRequests = DISABLE;
  hadc4.Init.Overrun = ADC_OVR_DATA_PRESERVED;
  hadc4.Init.OversamplingMode = DISABLE;
  if (HAL_ADC_Init(&hadc4) != HAL_OK)
  {
    Error_Handler();
  }

  /** Configure Regular Channel
  */
  sConfig.Channel = ADC_CHANNEL_1;
  sConfig.Rank = ADC_REGULAR_RANK_1;
  sConfig.SamplingTime = ADC_SAMPLETIME_2CYCLES_5;
  sConfig.SingleDiff = ADC_SINGLE_ENDED;
  sConfig.OffsetNumber = ADC_OFFSET_NONE;
  sConfig.Offset = 0;
  if (HAL_ADC_ConfigChannel(&hadc4, &sConfig) != HAL_OK)
  {
    Error_Handler();
  }

}

static void MX_DAC1_Init(void)
{

  DAC_ChannelConfTypeDef sConfig = {0};

  /** DAC Initialization
  */
  hdac1.Instance = DAC1;
  if (HAL_DAC_Init(&hdac1) != HAL_OK)
  {
    Error_Handler();
  }

  /** DAC channel OUT1 config
  */
  sConfig.DAC_HighFrequency = DAC_HIGH_FREQUENCY_INTERFACE_MODE_AUTOMATIC;
  sConfig.DAC_DMADoubleDataMode = DISABLE;
  sConfig.DAC_SignedFormat = DISABLE;
  sConfig.DAC_SampleAndHold = DAC_SAMPLEANDHOLD_DISABLE;
  sConfig.DAC_Trigger = DAC_TRIGGER_NONE;
  sConfig.DAC_Trigger2 = DAC_TRIGGER_NONE;
  sConfig.DAC_OutputBuffer = DAC_OUTPUTBUFFER_ENABLE;
  sConfig.DAC_ConnectOnChipPeripheral = DAC_CHIPCONNECT_BOTH;
  sConfig.DAC_UserTrimming = DAC_TRIMMING_FACTORY;
  if (HAL_DAC_ConfigChannel(&hdac1, &sConfig, DAC_CHANNEL_1) != HAL_OK)
  {
    Error_Handler();
  }

}

static void MX_OPAMP4_Init(void)
{

  hopamp4.Instance = OPAMP4;
  hopamp4.Init.PowerMode = OPAMP_POWERMODE_NORMALSPEED;
  hopamp4.Init.Mode = OPAMP_STANDALONE_MODE;
  hopamp4.Init.InvertingInput = OPAMP_INVERTINGINPUT_IO0;
  hopamp4.Init.NonInvertingInput = OPAMP_NONINVERTINGINPUT_IO2;
  hopamp4.Init.InternalOutput = DISABLE;
  hopamp4.Init.TimerControlledMuxmode = OPAMP_TIMERCONTROLLEDMUXMODE_DISABLE;
  hopamp4.Init.UserTrimming = OPAMP_TRIMMING_FACTORY;
  if (HAL_OPAMP_Init(&hopamp4) != HAL_OK)
  {
    Error_Handler();
  }

}

static void MX_OPAMP5_Init(void)
{

  hopamp5.Instance = OPAMP5;
  hopamp5.Init.PowerMode = OPAMP_POWERMODE_NORMALSPEED;
  hopamp5.Init.Mode = OPAMP_STANDALONE_MODE;
  hopamp5.Init.InvertingInput = OPAMP_INVERTINGINPUT_IO0;
  hopamp5.Init.NonInvertingInput = OPAMP_NONINVERTINGINPUT_IO0;
  hopamp5.Init.InternalOutput = DISABLE;
  hopamp5.Init.TimerControlledMuxmode = OPAMP_TIMERCONTROLLEDMUXMODE_DISABLE;
  hopamp5.Init.UserTrimming = OPAMP_TRIMMING_FACTORY;
  if (HAL_OPAMP_Init(&hopamp5) != HAL_OK)
  {
    Error_Handler();
  }

}

static void MX_SPI1_Init(void)
{

  /* SPI1 parameter configuration*/
  hspi1.Instance = SPI1;
  hspi1.Init.Mode = SPI_MODE_SLAVE;
  hspi1.Init.Direction = SPI_DIRECTION_2LINES;
  hspi1.Init.DataSize = SPI_DATASIZE_4BIT;
  hspi1.Init.CLKPolarity = SPI_POLARITY_LOW;
  hspi1.Init.CLKPhase = SPI_PHASE_1EDGE;
  hspi1.Init.NSS = SPI_NSS_HARD_INPUT;
  hspi1.Init.FirstBit = SPI_FIRSTBIT_MSB;
  hspi1.Init.TIMode = SPI_TIMODE_DISABLE;
  hspi1.Init.CRCCalculation = SPI_CRCCALCULATION_DISABLE;
  hspi1.Init.CRCPolynomial = 7;
  hspi1.Init.CRCLength = SPI_CRC_LENGTH_DATASIZE;
  hspi1.Init.NSSPMode = SPI_NSS_PULSE_DISABLE;
  if (HAL_SPI_Init(&hspi1) != HAL_OK)
  {
    Error_Handler();
  }

}

static void MX_TIM1_Init(void)
{

  TIM_SlaveConfigTypeDef sSlaveConfig = {0};
  TIM_MasterConfigTypeDef sMasterConfig = {0};
  TIMEx_BreakInputConfigTypeDef sBreakInputConfig = {0};
  TIM_OC_InitTypeDef sConfigOC = {0};
  TIM_BreakDeadTimeConfigTypeDef sBreakDeadTimeConfig = {0};

  htim1.Instance = TIM1;
  htim1.Init.Prescaler = 0;
  htim1.Init.CounterMode = TIM_COUNTERMODE_UP;
  htim1.Init.Period = 65535;
  htim1.Init.ClockDivision = TIM_CLOCKDIVISION_DIV1;
  htim1.Init.RepetitionCounter = 0;
  htim1.Init.AutoReloadPreload = TIM_AUTORELOAD_PRELOAD_DISABLE;
  if (HAL_TIM_Base_Init(&htim1) != HAL_OK)
  {
    Error_Handler();
  }
  if (HAL_TIM_PWM_Init(&htim1) != HAL_OK)
  {
    Error_Handler();
  }
  sSlaveConfig.SlaveMode = TIM_SLAVEMODE_TRIGGER;
  sSlaveConfig.InputTrigger = TIM_TS_ITR1;
  if (HAL_TIM_SlaveConfigSynchro(&htim1, &sSlaveConfig) != HAL_OK)
  {
    Error_Handler();
  }
  sMasterConfig.MasterOutputTrigger = TIM_TRGO_RESET;
  sMasterConfig.MasterOutputTrigger2 = TIM_TRGO2_RESET;
  sMasterConfig.MasterSlaveMode = TIM_MASTERSLAVEMODE_DISABLE;
  if (HAL_TIMEx_MasterConfigSynchronization(&htim1, &sMasterConfig) != HAL_OK)
  {
    Error_Handler();
  }
  sBreakInputConfig.Source = TIM_BREAKINPUTSOURCE_BKIN;
  sBreakInputConfig.Enable = TIM_BREAKINPUTSOURCE_ENABLE;
  sBreakInputConfig.Polarity = TIM_BREAKINPUTSOURCE_POLARITY_HIGH;
  if (HAL_TIMEx_ConfigBreakInput(&htim1, TIM_BREAKINPUT_BRK, &sBreakInputConfig) != HAL_OK)
  {
    Error_Handler();
  }
  if (HAL_TIMEx_ConfigBreakInput(&htim1, TIM_BREAKINPUT_BRK2, &sBreakInputConfig) != HAL_OK)
  {
    Error_Handler();
  }
  sConfigOC.OCMode = TIM_OCMODE_PWM1;
  sConfigOC.Pulse = 0;
  sConfigOC.OCPolarity = TIM_OCPOLARITY_HIGH;
  sConfigOC.OCNPolarity = TIM_OCNPOLARITY_HIGH;
  sConfigOC.OCFastMode = TIM_OCFAST_DISABLE;
  sConfigOC.OCIdleState = TIM_OCIDLESTATE_RESET;
  sConfigOC.OCNIdleState = TIM_OCNIDLESTATE_RESET;
  if (HAL_TIM_PWM_ConfigChannel(&htim1, &sConfigOC, TIM_CHANNEL_3) != HAL_OK)
  {
    Error_Handler();
  }
  sBreakDeadTimeConfig.OffStateRunMode = TIM_OSSR_ENABLE;
  sBreakDeadTimeConfig.OffStateIDLEMode = TIM_OSSI_ENABLE;
  sBreakDeadTimeConfig.LockLevel = TIM_LOCKLEVEL_OFF;
  sBreakDeadTimeConfig.DeadTime = 0;
  sBreakDeadTimeConfig.BreakState = TIM_BREAK_ENABLE;
  sBreakDeadTimeConfig.BreakPolarity = TIM_BREAKPOLARITY_HIGH;
  sBreakDeadTimeConfig.BreakFilter = 0;
  sBreakDeadTimeConfig.BreakAFMode = TIM_BREAK_AFMODE_INPUT;
  sBreakDeadTimeConfig.Break2State = TIM_BREAK2_ENABLE;
  sBreakDeadTimeConfig.Break2Polarity = TIM_BREAK2POLARITY_HIGH;
  sBreakDeadTimeConfig.Break2Filter = 0;
  sBreakDeadTimeConfig.Break2AFMode = TIM_BREAK_AFMODE_INPUT;
  sBreakDeadTimeConfig.AutomaticOutput = TIM_AUTOMATICOUTPUT_DISABLE;
  if (HAL_TIMEx_ConfigBreakDeadTime(&htim1, &sBreakDeadTimeConfig) != HAL_OK)
  {
    Error_Handler();
  }
  HAL_TIM_MspPostInit(&htim1);

}

static void MX_TIM2_Init(void)
{

  TIM_Encoder_InitTypeDef sConfig = {0};
  TIM_MasterConfigTypeDef sMasterConfig = {0};
  TIM_IC_InitTypeDef sConfigIC = {0};

  htim2.Instance = TIM2;
  htim2.Init.Prescaler = 0;
  htim2.Init.CounterMode = TIM_COUNTERMODE_UP;
  htim2.Init.Period = 4294967295;
  htim2.Init.ClockDivision = TIM_CLOCKDIVISION_DIV1;
  htim2.Init.AutoReloadPreload = TIM_AUTORELOAD_PRELOAD_DISABLE;
  if (HAL_TIM_IC_Init(&htim2) != HAL_OK)
  {
    Error_Handler();
  }
  sConfig.EncoderMode = TIM_ENCODERMODE_TI1;
  sConfig.IC1Polarity = TIM_ICPOLARITY_RISING;
  sConfig.IC1Selection = TIM_ICSELECTION_DIRECTTI;
  sConfig.IC1Prescaler = TIM_ICPSC_DIV1;
  sConfig.IC1Filter = 0;
  sConfig.IC2Polarity = TIM_ICPOLARITY_RISING;
  sConfig.IC2Selection = TIM_ICSELECTION_DIRECTTI;
  sConfig.IC2Prescaler = TIM_ICPSC_DIV1;
  sConfig.IC2Filter = 0;
  if (HAL_TIM_Encoder_Init(&htim2, &sConfig) != HAL_OK)
  {
    Error_Handler();
  }
  sMasterConfig.MasterOutputTrigger = TIM_TRGO_RESET;
  sMasterConfig.MasterSlaveMode = TIM_MASTERSLAVEMODE_DISABLE;
  if (HAL_TIMEx_MasterConfigSynchronization(&htim2, &sMasterConfig) != HAL_OK)
  {
    Error_Handler();
  }
  sConfigIC.ICPolarity = TIM_INPUTCHANNELPOLARITY_RISING;
  sConfigIC.ICSelection = TIM_ICSELECTION_DIRECTTI;
  sConfigIC.ICPrescaler = TIM_ICPSC_DIV1;
  sConfigIC.ICFilter = 0;
  if (HAL_TIM_IC_ConfigChannel(&htim2, &sConfigIC, TIM_CHANNEL_3) != HAL_OK)
  {
    Error_Handler();
  }

}

static void MX_TIM3_Init(void)
{

  TIM_ClockConfigTypeDef sClockSourceConfig = {0};
  TIM_HallSensor_InitTypeDef sConfig = {0};
  TIM_MasterConfigTypeDef sMasterConfig = {0};

  htim3.Instance = TIM3;
  htim3.Init.Prescaler = 0;
  htim3.Init.CounterMode = TIM_COUNTERMODE_UP;
  htim3.Init.Period = 65535;
  htim3.Init.ClockDivision = TIM_CLOCKDIVISION_DIV1;
  htim3.Init.AutoReloadPreload = TIM_AUTORELOAD_PRELOAD_DISABLE;
  if (HAL_TIM_Base_Init(&htim3) != HAL_OK)
  {
    Error_Handler();
  }
  sClockSourceConfig.ClockSource = TIM_CLOCKSOURCE_INTERNAL;
  if (HAL_TIM_ConfigClockSource(&htim3, &sClockSourceConfig) != HAL_OK)
  {
    Error_Handler();
  }
  sConfig.IC1Polarity = TIM_ICPOLARITY_RISING;
  sConfig.IC1Prescaler = TIM_ICPSC_DIV1;
  sConfig.IC1Filter = 0;
  sConfig.Commutation_Delay = 0;
  if (HAL_TIMEx_HallSensor_Init(&htim3, &sConfig) != HAL_OK)
  {
    Error_Handler();
  }
  sMasterConfig.MasterOutputTrigger = TIM_TRGO_OC2REF;
  sMasterConfig.MasterSlaveMode = TIM_MASTERSLAVEMODE_DISABLE;
  if (HAL_TIMEx_MasterConfigSynchronization(&htim3, &sMasterConfig) != HAL_OK)
  {
    Error_Handler();
  }

}

static void MX_TIM4_Init(void)
{

  TIM_ClockConfigTypeDef sClockSourceConfig = {0};
  TIM_HallSensor_InitTypeDef sConfig = {0};
  TIM_MasterConfigTypeDef sMasterConfig = {0};

  htim4.Instance = TIM4;
  htim4.Init.Prescaler = 0;
  htim4.Init.CounterMode = TIM_COUNTERMODE_UP;
  htim4.Init.Period = 65535;
  htim4.Init.ClockDivision = TIM_CLOCKDIVISION_DIV1;
  htim4.Init.AutoReloadPreload = TIM_AUTORELOAD_PRELOAD_DISABLE;
  if (HAL_TIM_Base_Init(&htim4) != HAL_OK)
  {
    Error_Handler();
  }
  sClockSourceConfig.ClockSource = TIM_CLOCKSOURCE_INTERNAL;
  if (HAL_TIM_ConfigClockSource(&htim4, &sClockSourceConfig) != HAL_OK)
  {
    Error_Handler();
  }
  sConfig.IC1Polarity = TIM_ICPOLARITY_RISING;
  sConfig.IC1Prescaler = TIM_ICPSC_DIV1;
  sConfig.IC1Filter = 0;
  sConfig.Commutation_Delay = 0;
  if (HAL_TIMEx_HallSensor_Init(&htim4, &sConfig) != HAL_OK)
  {
    Error_Handler();
  }
  sMasterConfig.MasterOutputTrigger = TIM_TRGO_OC2REF;
  sMasterConfig.MasterSlaveMode = TIM_MASTERSLAVEMODE_DISABLE;
  if (HAL_TIMEx_MasterConfigSynchronization(&htim4, &sMasterConfig) != HAL_OK)
  {
    Error_Handler();
  }

}

static void MX_TIM5_Init(void)
{

  TIM_Encoder_InitTypeDef sConfig = {0};
  TIM_MasterConfigTypeDef sMasterConfig = {0};
  TIM_IC_InitTypeDef sConfigIC = {0};

  htim5.Instance = TIM5;
  htim5.Init.Prescaler = 0;
  htim5.Init.CounterMode = TIM_COUNTERMODE_UP;
  htim5.Init.Period = 4294967295;
  htim5.Init.ClockDivision = TIM_CLOCKDIVISION_DIV1;
  htim5.Init.AutoReloadPreload = TIM_AUTORELOAD_PRELOAD_DISABLE;
  if (HAL_TIM_IC_Init(&htim5) != HAL_OK)
  {
    Error_Handler();
  }
  sConfig.EncoderMode = TIM_ENCODERMODE_TI1;
  sConfig.IC1Polarity = TIM_ICPOLARITY_RISING;
  sConfig.IC1Selection = TIM_ICSELECTION_DIRECTTI;
  sConfig.IC1Prescaler = TIM_ICPSC_DIV1;
  sConfig.IC1Filter = 0;
  sConfig.IC2Polarity = TIM_ICPOLARITY_RISING;
  sConfig.IC2Selection = TIM_ICSELECTION_DIRECTTI;
  sConfig.IC2Prescaler = TIM_ICPSC_DIV1;
  sConfig.IC2Filter = 0;
  if (HAL_TIM_Encoder_Init(&htim5, &sConfig) != HAL_OK)
  {
    Error_Handler();
  }
  sMasterConfig.MasterOutputTrigger = TIM_TRGO_RESET;
  sMasterConfig.MasterSlaveMode = TIM_MASTERSLAVEMODE_DISABLE;
  if (HAL_TIMEx_MasterConfigSynchronization(&htim5, &sMasterConfig) != HAL_OK)
  {
    Error_Handler();
  }
  sConfigIC.ICPolarity = TIM_INPUTCHANNELPOLARITY_RISING;
  sConfigIC.ICSelection = TIM_ICSELECTION_DIRECTTI;
  sConfigIC.ICPrescaler = TIM_ICPSC_DIV1;
  sConfigIC.ICFilter = 0;
  if (HAL_TIM_IC_ConfigChannel(&htim5, &sConfigIC, TIM_CHANNEL_3) != HAL_OK)
  {
    Error_Handler();
  }

}

static void MX_TIM8_Init(void)
{

  TIM_SlaveConfigTypeDef sSlaveConfig = {0};
  TIM_MasterConfigTypeDef sMasterConfig = {0};
  TIMEx_BreakInputConfigTypeDef sBreakInputConfig = {0};
  TIM_OC_InitTypeDef sConfigOC = {0};
  TIM_BreakDeadTimeConfigTypeDef sBreakDeadTimeConfig = {0};

  htim8.Instance = TIM8;
  htim8.Init.Prescaler = 0;
  htim8.Init.CounterMode = TIM_COUNTERMODE_UP;
  htim8.Init.Period = 65535;
  htim8.Init.ClockDivision = TIM_CLOCKDIVISION_DIV1;
  htim8.Init.RepetitionCounter = 0;
  htim8.Init.AutoReloadPreload = TIM_AUTORELOAD_PRELOAD_DISABLE;
  if (HAL_TIM_Base_Init(&htim8) != HAL_OK)
  {
    Error_Handler();
  }
  if (HAL_TIM_PWM_Init(&htim8) != HAL_OK)
  {
    Error_Handler();
  }
  if (HAL_TIM_OC_Init(&htim8) != HAL_OK)
  {
    Error_Handler();
  }
  sSlaveConfig.SlaveMode = TIM_SLAVEMODE_TRIGGER;
  sSlaveConfig.InputTrigger = TIM_TS_ITR1;
  if (HAL_TIM_SlaveConfigSynchro(&htim8, &sSlaveConfig) != HAL_OK)
  {
    Error_Handler();
  }
  sMasterConfig.MasterOutputTrigger = TIM_TRGO_RESET;
  sMasterConfig.MasterOutputTrigger2 = TIM_TRGO2_RESET;
  sMasterConfig.MasterSlaveMode = TIM_MASTERSLAVEMODE_DISABLE;
  if (HAL_TIMEx_MasterConfigSynchronization(&htim8, &sMasterConfig) != HAL_OK)
  {
    Error_Handler();
  }
  sBreakInputConfig.Source = TIM_BREAKINPUTSOURCE_BKIN;
  sBreakInputConfig.Enable = TIM_BREAKINPUTSOURCE_ENABLE;
  sBreakInputConfig.Polarity = TIM_BREAKINPUTSOURCE_POLARITY_HIGH;
  if (HAL_TIMEx_ConfigBreakInput(&htim8, TIM_BREAKINPUT_BRK, &sBreakInputConfig) != HAL_OK)
  {
    Error_Handler();
  }
  if (HAL_TIMEx_ConfigBreakInput(&htim8, TIM_BREAKINPUT_BRK2, &sBreakInputConfig) != HAL_OK)
  {
    Error_Handler();
  }
  sConfigOC.OCMode = TIM_OCMODE_PWM1;
  sConfigOC.Pulse = 0;
  sConfigOC.OCPolarity = TIM_OCPOLARITY_HIGH;
  sConfigOC.OCNPolarity = TIM_OCNPOLARITY_HIGH;
  sConfigOC.OCFastMode = TIM_OCFAST_DISABLE;
  sConfigOC.OCIdleState = TIM_OCIDLESTATE_RESET;
  sConfigOC.OCNIdleState = TIM_OCNIDLESTATE_RESET;
  if (HAL_TIM_PWM_ConfigChannel(&htim8, &sConfigOC, TIM_CHANNEL_1) != HAL_OK)
  {
    Error_Handler();
  }
  sConfigOC.OCMode = TIM_OCMODE_TIMING;
  if (HAL_TIM_OC_ConfigChannel(&htim8, &sConfigOC, TIM_CHANNEL_2) != HAL_OK)
  {
    Error_Handler();
  }
  if (HAL_TIM_OC_ConfigChannel(&htim8, &sConfigOC, TIM_CHANNEL_3) != HAL_OK)
  {
    Error_Handler();
  }
  sBreakDeadTimeConfig.OffStateRunMode = TIM_OSSR_ENABLE;
  sBreakDeadTimeConfig.OffStateIDLEMode = TIM_OSSI_ENABLE;
  sBreakDeadTimeConfig.LockLevel = TIM_LOCKLEVEL_OFF;
  sBreakDeadTimeConfig.DeadTime = 0;
  sBreakDeadTimeConfig.BreakState = TIM_BREAK_ENABLE;
  sBreakDeadTimeConfig.BreakPolarity = TIM_BREAKPOLARITY_HIGH;
  sBreakDeadTimeConfig.BreakFilter = 0;
  sBreakDeadTimeConfig.BreakAFMode = TIM_BREAK_AFMODE_INPUT;
  sBreakDeadTimeConfig.Break2State = TIM_BREAK2_ENABLE;
  sBreakDeadTimeConfig.Break2Polarity = TIM_BREAK2POLARITY_HIGH;
  sBreakDeadTimeConfig.Break2Filter = 0;
  sBreakDeadTimeConfig.Break2AFMode = TIM_BREAK_AFMODE_INPUT;
  sBreakDeadTimeConfig.AutomaticOutput = TIM_AUTOMATICOUTPUT_DISABLE;
  if (HAL_TIMEx_ConfigBreakDeadTime(&htim8, &sBreakDeadTimeConfig) != HAL_OK)
  {
    Error_Handler();
  }
  HAL_TIM_MspPostInit(&htim8);

}

static void MX_TIM16_Init(void)
{

  TIMEx_BreakInputConfigTypeDef sBreakInputConfig = {0};
  TIM_OC_InitTypeDef sConfigOC = {0};
  TIM_BreakDeadTimeConfigTypeDef sBreakDeadTimeConfig = {0};

  htim16.Instance = TIM16;
  htim16.Init.Prescaler = 0;
  htim16.Init.CounterMode = TIM_COUNTERMODE_UP;
  htim16.Init.Period = 65535;
  htim16.Init.ClockDivision = TIM_CLOCKDIVISION_DIV1;
  htim16.Init.RepetitionCounter = 0;
  htim16.Init.AutoReloadPreload = TIM_AUTORELOAD_PRELOAD_DISABLE;
  if (HAL_TIM_Base_Init(&htim16) != HAL_OK)
  {
    Error_Handler();
  }
  if (HAL_TIM_OC_Init(&htim16) != HAL_OK)
  {
    Error_Handler();
  }
  sBreakInputConfig.Source = TIM_BREAKINPUTSOURCE_BKIN;
  sBreakInputConfig.Enable = TIM_BREAKINPUTSOURCE_ENABLE;
  sBreakInputConfig.Polarity = TIM_BREAKINPUTSOURCE_POLARITY_HIGH;
  if (HAL_TIMEx_ConfigBreakInput(&htim16, TIM_BREAKINPUT_BRK, &sBreakInputConfig) != HAL_OK)
  {
    Error_Handler();
  }
  sConfigOC.OCMode = TIM_OCMODE_TIMING;
  sConfigOC.Pulse = 0;
  sConfigOC.OCPolarity = TIM_OCPOLARITY_HIGH;
  sConfigOC.OCNPolarity = TIM_OCNPOLARITY_HIGH;
  sConfigOC.OCFastMode = TIM_OCFAST_DISABLE;
  sConfigOC.OCIdleState = TIM_OCIDLESTATE_RESET;
  sConfigOC.OCNIdleState = TIM_OCNIDLESTATE_RESET;
  if (HAL_TIM_OC_ConfigChannel(&htim16, &sConfigOC, TIM_CHANNEL_1) != HAL_OK)
  {
    Error_Handler();
  }
  sBreakDeadTimeConfig.OffStateRunMode = TIM_OSSR_DISABLE;
  sBreakDeadTimeConfig.OffStateIDLEMode = TIM_OSSI_DISABLE;
  sBreakDeadTimeConfig.LockLevel = TIM_LOCKLEVEL_OFF;
  sBreakDeadTimeConfig.DeadTime = 0;
  sBreakDeadTimeConfig.BreakState = TIM_BREAK_ENABLE;
  sBreakDeadTimeConfig.BreakPolarity = TIM_BREAKPOLARITY_HIGH;
  sBreakDeadTimeConfig.BreakFilter = 0;
  sBreakDeadTimeConfig.AutomaticOutput = TIM_AUTOMATICOUTPUT_DISABLE;
  if (HAL_TIMEx_ConfigBreakDeadTime(&htim16, &sBreakDeadTimeConfig) != HAL_OK)
  {
    Error_Handler();
  }
  HAL_TIM_MspPostInit(&htim16);

}

static void MX_TIM17_Init(void)
{

  TIMEx_BreakInputConfigTypeDef sBreakInputConfig = {0};
  TIM_OC_InitTypeDef sConfigOC = {0};
  TIM_BreakDeadTimeConfigTypeDef sBreakDeadTimeConfig = {0};

  htim17.Instance = TIM17;
  htim17.Init.Prescaler = 0;
  htim17.Init.CounterMode = TIM_COUNTERMODE_UP;
  htim17.Init.Period = 65535;
  htim17.Init.ClockDivision = TIM_CLOCKDIVISION_DIV1;
  htim17.Init.RepetitionCounter = 0;
  htim17.Init.AutoReloadPreload = TIM_AUTORELOAD_PRELOAD_DISABLE;
  if (HAL_TIM_Base_Init(&htim17) != HAL_OK)
  {
    Error_Handler();
  }
  if (HAL_TIM_OC_Init(&htim17) != HAL_OK)
  {
    Error_Handler();
  }
  sBreakInputConfig.Source = TIM_BREAKINPUTSOURCE_BKIN;
  sBreakInputConfig.Enable = TIM_BREAKINPUTSOURCE_ENABLE;
  sBreakInputConfig.Polarity = TIM_BREAKINPUTSOURCE_POLARITY_HIGH;
  if (HAL_TIMEx_ConfigBreakInput(&htim17, TIM_BREAKINPUT_BRK, &sBreakInputConfig) != HAL_OK)
  {
    Error_Handler();
  }
  sConfigOC.OCMode = TIM_OCMODE_TIMING;
  sConfigOC.Pulse = 0;
  sConfigOC.OCPolarity = TIM_OCPOLARITY_HIGH;
  sConfigOC.OCNPolarity = TIM_OCNPOLARITY_HIGH;
  sConfigOC.OCFastMode = TIM_OCFAST_DISABLE;
  sConfigOC.OCIdleState = TIM_OCIDLESTATE_RESET;
  sConfigOC.OCNIdleState = TIM_OCNIDLESTATE_RESET;
  if (HAL_TIM_OC_ConfigChannel(&htim17, &sConfigOC, TIM_CHANNEL_1) != HAL_OK)
  {
    Error_Handler();
  }
  sBreakDeadTimeConfig.OffStateRunMode = TIM_OSSR_DISABLE;
  sBreakDeadTimeConfig.OffStateIDLEMode = TIM_OSSI_DISABLE;
  sBreakDeadTimeConfig.LockLevel = TIM_LOCKLEVEL_OFF;
  sBreakDeadTimeConfig.DeadTime = 0;
  sBreakDeadTimeConfig.BreakState = TIM_BREAK_ENABLE;
  sBreakDeadTimeConfig.BreakPolarity = TIM_BREAKPOLARITY_HIGH;
  sBreakDeadTimeConfig.BreakFilter = 0;
  sBreakDeadTimeConfig.AutomaticOutput = TIM_AUTOMATICOUTPUT_DISABLE;
  if (HAL_TIMEx_ConfigBreakDeadTime(&htim17, &sBreakDeadTimeConfig) != HAL_OK)
  {
    Error_Handler();
  }
  HAL_TIM_MspPostInit(&htim17);

}

static void MX_TIM20_Init(void)
{

  TIM_SlaveConfigTypeDef sSlaveConfig = {0};
  TIM_MasterConfigTypeDef sMasterConfig = {0};
  TIMEx_BreakInputConfigTypeDef sBreakInputConfig = {0};
  TIM_OC_InitTypeDef sConfigOC = {0};
  TIM_BreakDeadTimeConfigTypeDef sBreakDeadTimeConfig = {0};

  htim20.Instance = TIM20;
  htim20.Init.Prescaler = 0;
  htim20.Init.CounterMode = TIM_COUNTERMODE_UP;
  htim20.Init.Period = 65535;
  htim20.Init.ClockDivision = TIM_CLOCKDIVISION_DIV1;
  htim20.Init.RepetitionCounter = 0;
  htim20.Init.AutoReloadPreload = TIM_AUTORELOAD_PRELOAD_DISABLE;
  if (HAL_TIM_Base_Init(&htim20) != HAL_OK)
  {
    Error_Handler();
  }
  if (HAL_TIM_PWM_Init(&htim20) != HAL_OK)
  {
    Error_Handler();
  }
  if (HAL_TIM_OC_Init(&htim20) != HAL_OK)
  {
    Error_Handler();
  }
  sSlaveConfig.SlaveMode = TIM_SLAVEMODE_TRIGGER;
  sSlaveConfig.InputTrigger = TIM_TS_ITR1;
  if (HAL_TIM_SlaveConfigSynchro(&htim20, &sSlaveConfig) != HAL_OK)
  {
    Error_Handler();
  }
  sMasterConfig.MasterOutputTrigger = TIM_TRGO_RESET;
  sMasterConfig.MasterOutputTrigger2 = TIM_TRGO2_RESET;
  sMasterConfig.MasterSlaveMode = TIM_MASTERSLAVEMODE_DISABLE;
  if (HAL_TIMEx_MasterConfigSynchronization(&htim20, &sMasterConfig) != HAL_OK)
  {
    Error_Handler();
  }
  sBreakInputConfig.Source = TIM_BREAKINPUTSOURCE_BKIN;
  sBreakInputConfig.Enable = TIM_BREAKINPUTSOURCE_ENABLE;
  sBreakInputConfig.Polarity = TIM_BREAKINPUTSOURCE_POLARITY_HIGH;
  if (HAL_TIMEx_ConfigBreakInput(&htim20, TIM_BREAKINPUT_BRK, &sBreakInputConfig) != HAL_OK)
  {
    Error_Handler();
  }
  if (HAL_TIMEx_ConfigBreakInput(&htim20, TIM_BREAKINPUT_BRK2, &sBreakInputConfig) != HAL_OK)
  {
    Error_Handler();
  }
  sConfigOC.OCMode = TIM_OCMODE_PWM1;
  sConfigOC.Pulse = 0;
  sConfigOC.OCPolarity = TIM_OCPOLARITY_HIGH;
  sConfigOC.OCNPolarity = TIM_OCNPOLARITY_HIGH;
  sConfigOC.OCFastMode = TIM_OCFAST_DISABLE;
  sConfigOC.OCIdleState = TIM_OCIDLESTATE_RESET;
  sConfigOC.OCNIdleState = TIM_OCNIDLESTATE_RESET;
  if (HAL_TIM_PWM_ConfigChannel(&htim20, &sConfigOC, TIM_CHANNEL_2) != HAL_OK)
  {
    Error_Handler();
  }
  sConfigOC.OCMode = TIM_OCMODE_TIMING;
  if (HAL_TIM_OC_ConfigChannel(&htim20, &sConfigOC, TIM_CHANNEL_3) != HAL_OK)
  {
    Error_Handler();
  }
  sBreakDeadTimeConfig.OffStateRunMode = TIM_OSSR_ENABLE;
  sBreakDeadTimeConfig.OffStateIDLEMode = TIM_OSSI_ENABLE;
  sBreakDeadTimeConfig.LockLevel = TIM_LOCKLEVEL_OFF;
  sBreakDeadTimeConfig.DeadTime = 0;
  sBreakDeadTimeConfig.BreakState = TIM_BREAK_ENABLE;
  sBreakDeadTimeConfig.BreakPolarity = TIM_BREAKPOLARITY_HIGH;
  sBreakDeadTimeConfig.BreakFilter = 0;
  sBreakDeadTimeConfig.BreakAFMode = TIM_BREAK_AFMODE_INPUT;
  sBreakDeadTimeConfig.Break2State = TIM_BREAK2_ENABLE;
  sBreakDeadTimeConfig.Break2Polarity = TIM_BREAK2POLARITY_HIGH;
  sBreakDeadTimeConfig.Break2Filter = 0;
  sBreakDeadTimeConfig.Break2AFMode = TIM_BREAK_AFMODE_INPUT;
  sBreakDeadTimeConfig.AutomaticOutput = TIM_AUTOMATICOUTPUT_DISABLE;
  if (HAL_TIMEx_ConfigBreakDeadTime(&htim20, &sBreakDeadTimeConfig) != HAL_OK)
  {
    Error_Handler();
  }
  HAL_TIM_MspPostInit(&htim20);

}

static void MX_USART1_UART_Init(void)
{

  huart1.Instance = USART1;
  huart1.Init.BaudRate = 115200;
  huart1.Init.WordLength = UART_WORDLENGTH_8B;
  huart1.Init.StopBits = UART_STOPBITS_1;
  huart1.Init.Parity = UART_PARITY_NONE;
  huart1.Init.Mode = UART_MODE_TX_RX;
  huart1.Init.HwFlowCtl = UART_HWCONTROL_NONE;
  huart1.Init.OverSampling = UART_OVERSAMPLING_16;
  huart1.Init.OneBitSampling = UART_ONE_BIT_SAMPLE_DISABLE;
  huart1.Init.ClockPrescaler = UART_PRESCALER_DIV1;
  huart1.AdvancedInit.AdvFeatureInit = UART_ADVFEATURE_NO_INIT;
  if (HAL_UART_Init(&huart1) != HAL_OK)
  {
    Error_Handler();
  }
  if (HAL_UARTEx_SetTxFifoThreshold(&huart1, UART_TXFIFO_THRESHOLD_1_8) != HAL_OK)
  {
    Error_Handler();
  }
  if (HAL_UARTEx_SetRxFifoThreshold(&huart1, UART_RXFIFO_THRESHOLD_1_8) != HAL_OK)
  {
    Error_Handler();
  }
  if (HAL_UARTEx_DisableFifoMode(&huart1) != HAL_OK)
  {
    Error_Handler();
  }

}

static void MX_DMA_Init(void)
{

  /* DMA controller clock enable */
  __HAL_RCC_DMAMUX1_CLK_ENABLE();
  __HAL_RCC_DMA1_CLK_ENABLE();
  __HAL_RCC_DMA2_CLK_ENABLE();

  /* DMA interrupt init */
  /* DMA1_Channel4_IRQn interrupt configuration */
  HAL_NVIC_SetPriority(DMA1_Channel4_IRQn, 0, 0);
  HAL_NVIC_EnableIRQ(DMA1_Channel4_IRQn);
  /* DMA2_Channel1_IRQn interrupt configuration */
  HAL_NVIC_SetPriority(DMA2_Channel1_IRQn, 0, 0);
  HAL_NVIC_EnableIRQ(DMA2_Channel1_IRQn);

}

static void MX_GPIO_Init(void)
{
  GPIO_InitTypeDef GPIO_InitStruct = {0};

  /* GPIO Ports Clock Enable */
  __HAL_RCC_GPIOE_CLK_ENABLE();
  __HAL_RCC_GPIOC_CLK_ENABLE();
  __HAL_RCC_GPIOF_CLK_ENABLE();
  __HAL_RCC_GPIOG_CLK_ENABLE();
  __HAL_RCC_GPIOA_CLK_ENABLE();
  __HAL_RCC_GPIOB_CLK_ENABLE();
  __HAL_RCC_GPIOD_CLK_ENABLE();

  /*Configure GPIO pin Output Level */
  HAL_GPIO_WritePin(M2_ENABLE1_GPIO_GPIO_Port, M2_ENABLE1_GPIO_Pin, GPIO_PIN_RESET);

  /*Configure GPIO pin Output Level */
  HAL_GPIO_WritePin(GPIOF, GPIO_OUT_LED_GREEN_Pin|M1_ENABLE1_GPIO_Pin|M1_ENABLE2_GPIO_Pin|M2_ENABLE2_GPIO_Pin
                          |GPIO_OUT_INRUSH_Pin|GPIO_OUT_ID_ENABLE_Pin, GPIO_PIN_RESET);

  /*Configure GPIO pin Output Level */
  HAL_GPIO_WritePin(M3_ENABLE1_GPIO_GPIO_Port, M3_ENABLE1_GPIO_Pin, GPIO_PIN_RESET);

  /*Configure GPIO pin Output Level */
  HAL_GPIO_WritePin(GPIOG, GPIO_OUT_M2_ENABLE_Pin|GPIO_OUT_M1_ENABLE_Pin|GPIO_OUT_M1_BRAKE_Pin, GPIO_PIN_RESET);

  /*Configure GPIO pin Output Level */
  HAL_GPIO_WritePin(GPIOD, GPIO_OUT_M22_BRAKE_Pin|M3_ENABLE2_GPIO_Pin|GPIO_OUT_LED_YELLOW_Pin|GPIO_OUT_LED_RED_Pin, GPIO_PIN_RESET);

  /*Configure GPIO pin : M2_ENABLE1_GPIO_Pin */
  GPIO_InitStruct.Pin = M2_ENABLE1_GPIO_Pin;
  GPIO_InitStruct.Mode = GPIO_MODE_OUTPUT_PP;
  GPIO_InitStruct.Pull = GPIO_NOPULL;
  GPIO_InitStruct.Speed = GPIO_SPEED_FREQ_LOW;
  HAL_GPIO_Init(M2_ENABLE1_GPIO_GPIO_Port, &GPIO_InitStruct);

  /*Configure GPIO pin : PC13 */
  GPIO_InitStruct.Pin = GPIO_PIN_13;
  GPIO_InitStruct.Mode = GPIO_MODE_INPUT;
  GPIO_InitStruct.Pull = GPIO_PULLUP;
  HAL_GPIO_Init(GPIOC, &GPIO_InitStruct);

  /*Configure GPIO pins : GPIO_OUT_LED_GREEN_Pin M1_ENABLE1_GPIO_Pin M1_ENABLE2_GPIO_Pin GPIO_OUT_INRUSH_Pin
                           GPIO_OUT_ID_ENABLE_Pin */
  GPIO_InitStruct.Pin = GPIO_OUT_LED_GREEN_Pin|M1_ENABLE1_GPIO_Pin|M1_ENABLE2_GPIO_Pin|GPIO_OUT_INRUSH_Pin
                          |GPIO_OUT_ID_ENABLE_Pin;
  GPIO_InitStruct.Mode = GPIO_MODE_OUTPUT_PP;
  GPIO_InitStruct.Pull = GPIO_NOPULL;
  GPIO_InitStruct.Speed = GPIO_SPEED_FREQ_LOW;
  HAL_GPIO_Init(GPIOF, &GPIO_InitStruct);

  /*Configure GPIO pin : BUTTON_RESET_Pin */
  GPIO_InitStruct.Pin = BUTTON_RESET_Pin;
  GPIO_InitStruct.Mode = GPIO_MODE_INPUT;
  GPIO_InitStruct.Pull = GPIO_NOPULL;
  HAL_GPIO_Init(BUTTON_RESET_GPIO_Port, &GPIO_InitStruct);

  /*Configure GPIO pin : M2_ENABLE2_GPIO_Pin */
  GPIO_InitStruct.Pin = M2_ENABLE2_GPIO_Pin;
  GPIO_InitStruct.Mode = GPIO_MODE_OUTPUT_PP;
  GPIO_InitStruct.Pull = GPIO_NOPULL;
  GPIO_InitStruct.Speed = GPIO_SPEED_FREQ_VERY_HIGH;
  HAL_GPIO_Init(M2_ENABLE2_GPIO_GPIO_Port, &GPIO_InitStruct);

  /*Configure GPIO pins : PB0 PB1 */
  GPIO_InitStruct.Pin = GPIO_PIN_0|GPIO_PIN_1;
  GPIO_InitStruct.Mode = GPIO_MODE_ANALOG;
  GPIO_InitStruct.Pull = GPIO_NOPULL;
  HAL_GPIO_Init(GPIOB, &GPIO_InitStruct);

  /*Configure GPIO pin : M3_ENABLE1_GPIO_Pin */
  GPIO_InitStruct.Pin = M3_ENABLE1_GPIO_Pin;
  GPIO_InitStruct.Mode = GPIO_MODE_OUTPUT_PP;
  GPIO_InitStruct.Pull = GPIO_NOPULL;
  GPIO_InitStruct.Speed = GPIO_SPEED_FREQ_LOW;
  HAL_GPIO_Init(M3_ENABLE1_GPIO_GPIO_Port, &GPIO_InitStruct);

  /*Configure GPIO pins : GPIO_OUT_M2_ENABLE_Pin GPIO_OUT_M1_ENABLE_Pin GPIO_OUT_M1_BRAKE_Pin */
  GPIO_InitStruct.Pin = GPIO_OUT_M2_ENABLE_Pin|GPIO_OUT_M1_ENABLE_Pin|GPIO_OUT_M1_BRAKE_Pin;
  GPIO_InitStruct.Mode = GPIO_MODE_OUTPUT_PP;
  GPIO_InitStruct.Pull = GPIO_NOPULL;
  GPIO_InitStruct.Speed = GPIO_SPEED_FREQ_LOW;
  HAL_GPIO_Init(GPIOG, &GPIO_InitStruct);

  /*Configure GPIO pins : GPIO_OUT_M22_BRAKE_Pin M3_ENABLE2_GPIO_Pin GPIO_OUT_LED_YELLOW_Pin GPIO_OUT_LED_RED_Pin */
  GPIO_InitStruct.Pin = GPIO_OUT_M22_BRAKE_Pin|M3_ENABLE2_GPIO_Pin|GPIO_OUT_LED_YELLOW_Pin|GPIO_OUT_LED_RED_Pin;
  GPIO_InitStruct.Mode = GPIO_MODE_OUTPUT_PP;
  GPIO_InitStruct.Pull = GPIO_NOPULL;
  GPIO_InitStruct.Speed = GPIO_SPEED_FREQ_LOW;
  HAL_GPIO_Init(GPIOD, &GPIO_InitStruct);

}

/* USER CODE BEGIN 4 */
//Called when first half of buffer is filled
void HAL_ADC_ConvHalfCpltCallback(ADC_HandleTypeDef* hadc){
	HAL_GPIO_WritePin(GPIOF, GPIO_PIN_2, GPIO_PIN_SET);

	if(hadc->DMA_Handle->Instance == DMA1_Channel4)
	{
		au32_midway_ticksADC1 = DWT->CYCCNT;
	} else if (hadc->DMA_Handle->Instance == DMA2_Channel1)
	{
		au32_midway_ticksADC3 = DWT->CYCCNT;
	}

	Process_HalfBuffer(hadc, 1);
}

//Called when buffer is completely filled
void HAL_ADC_ConvCpltCallback(ADC_HandleTypeDef* hadc){
	HAL_GPIO_WritePin(GPIOF, GPIO_PIN_2, GPIO_PIN_RESET);

	if(hadc->DMA_Handle->Instance == DMA1_Channel4)
	{
		au32_end_ticksADC1 = DWT->CYCCNT;
	} else if (hadc->DMA_Handle->Instance == DMA2_Channel1)
	{
		au32_end_ticksADC3 = DWT->CYCCNT;
	}

	//numOfConversions++;

	/*
	if(numOfConversions > 65000)
	{
		if(hadc->DMA_Handle->Instance == DMA1_Channel4)
		{
			indexStoppedADC1 = numOfConversions;
		} else if (hadc->DMA_Handle->Instance == DMA2_Channel1)
		{
			indexStoppedADC3 = numOfConversions;
		}
		HAL_ADCEx_MultiModeStop_DMA(hadc);
	}
	*/

	Process_HalfBuffer(hadc, 2);
}

uint32_t DWT_Delay_Init(void)
{
    /* Disable TRC */
    CoreDebug->DEMCR &= ~CoreDebug_DEMCR_TRCENA_Msk; // ~0x01000000;
    /* Enable TRC */
    CoreDebug->DEMCR |=  CoreDebug_DEMCR_TRCENA_Msk; // 0x01000000;

    /* Disable clock cycle counter */
    DWT->CTRL &= ~DWT_CTRL_CYCCNTENA_Msk; //~0x00000001;
    /* Enable  clock cycle counter */
    DWT->CTRL |=  DWT_CTRL_CYCCNTENA_Msk; //0x00000001;

    /* Reset the clock cycle counter value */
    DWT->CYCCNT = 0;

    /* 3 NO OPERATION instructions */
    __ASM volatile ("NOP");
    __ASM volatile ("NOP");
    __ASM volatile ("NOP");

    /* Check if clock cycle counter has started */
    if(DWT->CYCCNT)
    {
       return 0; /*clock cycle counter started*/
    }
    else
    {
      return 1; /*clock cycle counter not started*/
    }
}

void Process_HalfBuffer(ADC_HandleTypeDef* hadc, int cycle) { //If cycle = 1 we are dealing with the first half of the input buffer, if cycle = 2 then the second half

	static float leftIn, rightIn;

	uint16_t* integerBuffer;

	static uint16_t fftIndexADC12 = 0;
	static uint16_t fftIndexADC34 = 0;
	int ADC = 0;

	if(hadc->DMA_Handle->Instance == DMA1_Channel4)
	{
		ADC = 1;
	} else if (hadc->DMA_Handle->Instance == DMA2_Channel1)
	{
		ADC = 3;
	}

	if(ADC == 1)
	{
		if(cycle == 1)
		{
			integerBuffer = adc_buf1;
		} else if (cycle == 2)
		{
			integerBuffer = &adc_buf1[ADC_BUF_LEN];
		}
	} else if (ADC == 3)
	{
		if(cycle == 1)
		{
			integerBuffer = adc_buf1;
		} else if (cycle == 2)
		{
			integerBuffer = &adc_buf1[ADC_BUF_LEN];
		}
	}

	for (uint16_t n = 0; n <(ADC_BUF_LEN/2) - 1; n += 2) {

		leftIn = ((float) integerBuffer[n] - (ADC_MAX/2)) / (ADC_MAX/2);
		rightIn = ((float) integerBuffer[n+1] - (ADC_MAX/2)) / (ADC_MAX/2);

		if(ADC == 1)
		{
		fftBufInADC1[fftIndexADC12] = leftIn;
		fftBufInADC2[fftIndexADC12] = rightIn;
		fftIndexADC12++;
		}

		if(ADC == 3)
		{
		fftBufInADC3[fftIndexADC34] = leftIn;
		fftBufInADC4[fftIndexADC34] = rightIn;
		fftIndexADC34++;
		}

	}

	if (fftIndexADC12 == ADC_BUF_LEN)
	{
		arm_rfft_fast_f32(&fftHandler, (float32_t *) &fftBufInADC1, (float32_t *) &fftBufOutADC1, 0);
		arm_rfft_fast_f32(&fftHandler, (float32_t *) &fftBufInADC2, (float32_t *) &fftBufOutADC2, 0);

		fftFlagADC12 = 1;
		fftIndexADC12 = 0;

		HAL_ADCEx_MultiModeStop_DMA(hadc);
	}

	if (fftIndexADC34 == ADC_BUF_LEN)
	{
		arm_rfft_fast_f32(&fftHandler, (float32_t *) &fftBufInADC3, (float32_t *) &fftBufOutADC3, 0);
		arm_rfft_fast_f32(&fftHandler, (float32_t *) &fftBufInADC4, (float32_t *) &fftBufOutADC4, 0);
		fftFlagADC34 = 1;

		fftIndexADC34 = 0;
		HAL_ADCEx_MultiModeStop_DMA(hadc);
	}

}
/* USER CODE END 4 */

void Error_Handler(void)
{
  /* USER CODE BEGIN Error_Handler_Debug */
  /* User can add his own implementation to report the HAL error return state */
  __disable_irq();

  /*
  while (1)
  {
	HAL_UART_Transmit(&huart1, (uint8_t*) errMsg, strlen(errMsg), HAL_MAX_DELAY);
  }
  */
  /* USER CODE END Error_Handler_Debug */
}
